VERSION ""

NS_ :

BS_:

BU_: BMS_Bermartec BMS_Bermartec_2 ESX_3CS Scanreco_RC

BO_ 3221225472 VECTOR__INDEPENDENT_SIG_MSG: 0 Vector__XXX
 SG_ BatteryStep : 0|8@1+ (1,0) [0|255] "" Vector__XXX
 SG_ ErrorWarning : 0|8@1+ (1,0) [0|255] "" Vector__XXX
 SG_ NodeStatus : 0|16@1+ (1,0) [0|65535] "" Vector__XXX
 SG_ SoCBat : 0|16@1+ (0.1,0) [0|6553.5] "%" Vector__XXX
 SG_ SoHBat : 0|16@1+ (0.1,0) [0|6553.5] "%" Vector__XXX
 SG_ BatteryStep : 0|8@1+ (1,0) [0|255] "" Vector__XXX
 SG_ ErrorWarning : 0|8@1+ (1,0) [0|255] "" Vector__XXX
 SG_ NodeStatus : 0|16@1+ (1,0) [0|65535] "" Vector__XXX
 SG_ SoCBat : 0|16@1+ (0.1,0) [0|6553.5] "%" Vector__XXX
 SG_ SoHBat : 0|16@1+ (0.1,0) [0|6553.5] "%" Vector__XXX
 SG_ ClearErrorBitList : 0|32@1+ (1,0) [0|4294967295] "" Vector__XXX
 SG_ ExternCommand : 0|16@1+ (1,0) [0|65535] "" Vector__XXX
 SG_ ClearErrorBitList : 0|32@1+ (1,0) [0|4294967295] "" Vector__XXX
 SG_ ExternCommand : 0|16@1+ (1,0) [0|65535] "" Vector__XXX
 SG_ Battery_Lvl : 0|2@1+ (1,0) [0|3] "" Vector__XXX
 SG_ P_1 : 0|1@1+ (1,0) [0|1] "" Vector__XXX
 SG_ P_10 : 0|1@1+ (1,0) [0|1] "" Vector__XXX
 SG_ P_10_2 : 0|1@1+ (1,0) [0|1] "" Vector__XXX
 SG_ P_11 : 0|1@1+ (1,0) [0|1] "" Vector__XXX
 SG_ P_11_2 : 0|1@1+ (1,0) [0|1] "" Vector__XXX
 SG_ P_12 : 0|1@1+ (1,0) [0|1] "" Vector__XXX
 SG_ P_12_2 : 0|1@1+ (1,0) [0|1] "" Vector__XXX
 SG_ P_13 : 0|1@1+ (1,0) [0|1] "" Vector__XXX
 SG_ P_13_2 : 0|1@1+ (1,0) [0|1] "" Vector__XXX
 SG_ P_14 : 0|1@1+ (1,0) [0|1] "" Vector__XXX
 SG_ P_14_2 : 0|1@1+ (1,0) [0|1] "" Vector__XXX
 SG_ P_1_2 : 0|1@1+ (1,0) [0|1] "" Vector__XXX
 SG_ P_2 : 0|1@1+ (1,0) [0|1] "" Vector__XXX
 SG_ P_2_2 : 0|1@1+ (1,0) [0|1] "" Vector__XXX
 SG_ P_3 : 0|1@1+ (1,0) [0|1] "" Vector__XXX
 SG_ P_3_2 : 0|1@1+ (1,0) [0|1] "" Vector__XXX
 SG_ P_4 : 0|1@1+ (1,0) [0|1] "" Vector__XXX
 SG_ P_4_2 : 0|1@1+ (1,0) [0|1] "" Vector__XXX
 SG_ P_5 : 0|1@1+ (1,0) [0|1] "" Vector__XXX
 SG_ P_5_2 : 0|1@1+ (1,0) [0|1] "" Vector__XXX
 SG_ P_6 : 0|1@1+ (1,0) [0|1] "" Vector__XXX
 SG_ P_6_2 : 0|1@1+ (1,0) [0|1] "" Vector__XXX
 SG_ P_7 : 0|1@1+ (1,0) [0|1] "" Vector__XXX
 SG_ P_7_2 : 0|1@1+ (1,0) [0|1] "" Vector__XXX
 SG_ P_8 : 0|1@1+ (1,0) [0|1] "" Vector__XXX
 SG_ P_8_2 : 0|1@1+ (1,0) [0|1] "" Vector__XXX
 SG_ P_9 : 0|1@1+ (1,0) [0|1] "" Vector__XXX
 SG_ P_9_2 : 0|1@1+ (1,0) [0|1] "" Vector__XXX
 SG_ RC_Stop : 0|8@1+ (1,0) [0|255] "" Vector__XXX
 SG_ AverageCellVoltage : 0|16@1+ (1,0) [0|65535] "mV" Vector__XXX
 SG_ HighestCellNumber : 0|8@1+ (1,0) [0|255] "" Vector__XXX
 SG_ HighestCellVoltage : 0|16@1+ (1,0) [0|65535] "mV" Vector__XXX
 SG_ LowestCellNumber : 0|8@1+ (1,0) [0|255] "" Vector__XXX
 SG_ LowestCellVoltage : 0|16@1+ (1,0) [0|65535] "mV" Vector__XXX
 SG_ AverageCellVoltage : 0|16@1+ (1,0) [0|65535] "mV" Vector__XXX
 SG_ HighestCellNumber : 0|8@1+ (1,0) [0|255] "" Vector__XXX
 SG_ HighestCellVoltage : 0|16@1+ (1,0) [0|65535] "mV" Vector__XXX
 SG_ LowestCellNumber : 0|8@1+ (1,0) [0|255] "" Vector__XXX
 SG_ LowestCellVoltage : 0|16@1+ (1,0) [0|65535] "mV" Vector__XXX
 SG_ Blackout : 0|1@1+ (1,0) [0|1] "" Vector__XXX
 SG_ Buzzer : 0|1@1+ (1,0) [0|1] "" Vector__XXX
 SG_ Frame1 : 0|8@1+ (1,0) [0|255] "" Vector__XXX
 SG_ LED_1 : 0|1@1+ (1,0) [0|1] "" Vector__XXX
 SG_ LED_2 : 0|1@1+ (1,0) [0|1] "" Vector__XXX
 SG_ LED_3 : 0|1@1+ (1,0) [0|1] "" Vector__XXX
 SG_ LED_4 : 0|1@1+ (1,0) [0|1] "" Vector__XXX
 SG_ LED_5 : 0|1@1+ (1,0) [0|1] "" Vector__XXX
 SG_ Vibrator : 0|1@1+ (1,0) [0|1] "" Vector__XXX
 SG_ AverageCellTemp : 0|16@1- (1,0) [-32768|32767] "degC" Vector__XXX
 SG_ BattVoltage : 0|16@1+ (0.1,0) [0|6553.5] "V" Vector__XXX
 SG_ HighestCellTemp : 0|16@1- (1,0) [-32768|32767] "degC" Vector__XXX
 SG_ LowestCellTemp : 0|16@1- (1,0) [-32768|32767] "degC" Vector__XXX
 SG_ AverageCellTemp : 0|16@1- (1,0) [-32768|32767] "degC" Vector__XXX
 SG_ BattVoltage : 0|16@1+ (0.1,0) [0|6553.5] "V" Vector__XXX
 SG_ HighestCellTemp : 0|16@1- (1,0) [-32768|32767] "degC" Vector__XXX
 SG_ LowestCellTemp : 0|16@1- (1,0) [-32768|32767] "degC" Vector__XXX
 SG_ Byte_1 : 0|8@1+ (1,0) [0|255] "" Vector__XXX
 SG_ Byte_2 : 0|8@1+ (1,0) [0|255] "" Vector__XXX
 SG_ Byte_3 : 0|8@1+ (1,0) [0|255] "" Vector__XXX
 SG_ Byte_4 : 0|8@1+ (1,0) [0|255] "" Vector__XXX
 SG_ Byte_5 : 0|8@1+ (1,0) [0|255] "" Vector__XXX
 SG_ Byte_6 : 0|8@1+ (1,0) [0|255] "" Vector__XXX
 SG_ Byte_7 : 0|8@1+ (1,0) [0|255] "" Vector__XXX
 SG_ Header : 0|8@1+ (1,0) [0|255] "" Vector__XXX
 SG_ CellVoltageDiff : 0|16@1- (1,0) [-32768|32767] "mV" Vector__XXX
 SG_ CurrBatt : 0|16@1- (0.1,0) [-3276.8|3276.7] "A" Vector__XXX
 SG_ MaxChargeCurrent : 0|16@1- (0.01,0) [-327.68|327.67] "A" Vector__XXX
 SG_ OutputStatus : 0|8@1+ (1,0) [0|255] "" Vector__XXX
 SG_ PrechargeInfo : 0|8@1+ (1,0) [0|255] "" Vector__XXX
 SG_ CellVoltageDiff : 0|16@1- (1,0) [-32768|32767] "mV" Vector__XXX
 SG_ CurrBatt : 0|16@1- (0.1,0) [-3276.8|3276.7] "A" Vector__XXX
 SG_ MaxChargeCurrent : 0|16@1- (0.01,0) [-327.68|327.67] "A" Vector__XXX
 SG_ OutputStatus : 0|8@1+ (1,0) [0|255] "" Vector__XXX
 SG_ PrechargeInfo : 0|8@1+ (1,0) [0|255] "" Vector__XXX
 SG_ ChargeCurrent : 0|16@1+ (0.01,0) [0|655.35] "A" Vector__XXX
 SG_ ChargerMaxVoltage : 0|16@1+ (0.1,0) [0|6553.5] "V" Vector__XXX
 SG_ CompanyName1 : 0|8@0+ (1,0) [0|255] "" Vector__XXX
 SG_ CompanyName2 : 0|8@0+ (1,0) [0|255] "" Vector__XXX
 SG_ HardwareNumber : 0|24@0+ (1,0) [0|16777215] "" Vector__XXX
 SG_ HardwarePlacement : 0|8@0+ (1,0) [0|255] "" Vector__XXX
 SG_ HardwareVersion : 0|8@0+ (1,0) [0|255] "" Vector__XXX
 SG_ NodeID : 0|8@0+ (1,0) [0|255] "" Vector__XXX
 SG_ CompanyName1 : 0|8@0+ (1,0) [0|255] "" Vector__XXX
 SG_ CompanyName2 : 0|8@0+ (1,0) [0|255] "" Vector__XXX
 SG_ HardwareNumber : 0|24@0+ (1,0) [0|16777215] "" Vector__XXX
 SG_ HardwarePlacement : 0|8@0+ (1,0) [0|255] "" Vector__XXX
 SG_ HardwareVersion : 0|8@0+ (1,0) [0|255] "" Vector__XXX
 SG_ NodeID : 0|8@0+ (1,0) [0|255] "" Vector__XXX

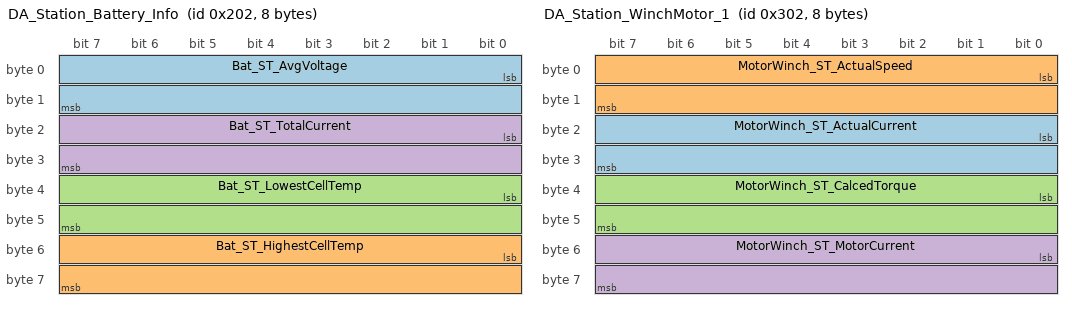
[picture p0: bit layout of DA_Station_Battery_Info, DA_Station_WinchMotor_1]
BO_ 514 DA_Station_Battery_Info: 8 ESX_3CS
 SG_ Bat_ST_AvgVoltage : 0|16@1+ (0.1,0) [0|6553.5] "V" Vector__XXX
 SG_ Bat_ST_HighestCellTemp : 48|16@1- (1,0) [-32768|32767] "°C" Vector__XXX
 SG_ Bat_ST_LowestCellTemp : 32|16@1- (1,0) [-32768|32767] "°C" Vector__XXX
 SG_ Bat_ST_TotalCurrent : 16|16@1- (0.1,0) [-3276.8|3276.7] "A" Vector__XXX

BO_ 770 DA_Station_WinchMotor_1: 8 ESX_3CS
 SG_ MotorWinch_ST_ActualCurrent : 16|16@1+ (1,0) [0|65535] "ADC" Vector__XXX
 SG_ MotorWinch_ST_ActualSpeed : 0|16@1- (1,0) [-32768|32767] "rpm" Vector__XXX
 SG_ MotorWinch_ST_CalcedTorque : 32|16@1- (0.1,0) [-3276.8|3276.7] "Nm" Vector__XXX
 SG_ MotorWinch_ST_MotorCurrent : 48|16@1- (1,0) [-32768|32767] "Arms" Vector__XXX

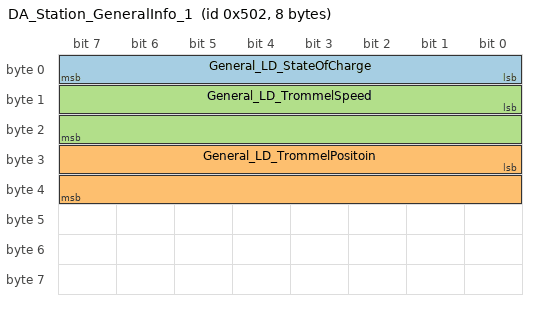
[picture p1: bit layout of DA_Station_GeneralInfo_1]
BO_ 1282 DA_Station_GeneralInfo_1: 8 ESX_3CS
 SG_ General_LD_StateOfCharge : 0|8@1+ (0.1,0) [0|25.5] "%" Vector__XXX
 SG_ General_LD_TrommelPositoin : 24|16@1- (1,0) [-32768|32767] "Digit" Vector__XXX
 SG_ General_LD_TrommelSpeed : 8|16@1- (0.1,0) [-3276.8|3276.7] "rpm" Vector__XXX

CM_ BO_ 3221225472 "This is a message for not used signals, created by Vector CANdb++ DBC OLE DB Provider.";
BA_DEF_  "DBName" STRING ;
BA_DEF_ BO_  "GenMsgCycleTime" INT 0 0;
BA_DEF_ BO_  "GenMsgSendType" ENUM  "Cyclic","OnEvent";
BA_DEF_ SG_  "GenSigStartValue" INT 0 0;
BA_DEF_DEF_  "DBName" "";
BA_DEF_DEF_  "GenMsgCycleTime" 0;
BA_DEF_DEF_  "GenMsgSendType" "";
BA_DEF_DEF_  "GenSigStartValue" 0;
BA_ "DBName" "CAN1";
BA_ "GenMsgSendType" BO_ 514 0;
BA_ "GenMsgCycleTime" BO_ 514 100;
BA_ "GenMsgSendType" BO_ 770 0;
BA_ "GenMsgCycleTime" BO_ 770 100;
BA_ "GenMsgSendType" BO_ 1282 0;
BA_ "GenMsgCycleTime" BO_ 1282 100;
BA_ "GenSigStartValue" SG_ 3221225472 NodeStatus 32768;
BA_ "GenSigStartValue" SG_ 3221225472 NodeStatus 32768;
